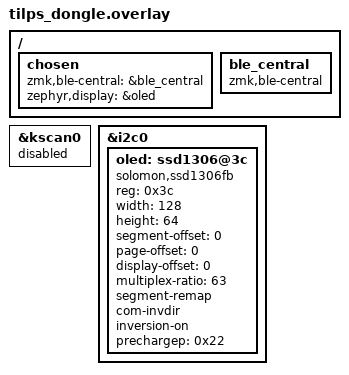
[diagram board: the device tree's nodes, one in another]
/*
 * Copyright (c) 2020 The ZMK Contributors
 *
 * SPDX-License-Identifier: MIT
 */

#include "tilps.dtsi"

/ {
    chosen {
        /delete-property/ zmk,kscan;
        zmk,ble-central = &ble_central;
        zephyr,display = &oled;
    };

    ble_central: ble_central {
        compatible = "zmk,ble-central";
    };
};

&kscan0 {
    status = "disabled";
};

&i2c0 {
    status = "okay";

    oled: ssd1306@3c {
        compatible = "solomon,ssd1306fb";
        reg = <0x3c>;
        width = <128>;
        height = <64>;
        segment-offset = <0>;
        page-offset = <0>;
        display-offset = <0>;
        multiplex-ratio = <63>;
        segment-remap;
        com-invdir;
        inversion-on;
        prechargep = <0x22>;
    };
};

